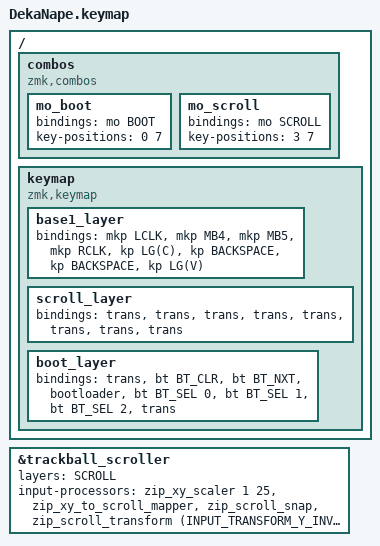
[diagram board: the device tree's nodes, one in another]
/*
 * Copyright (c) 2020 The ZMK Contributors
 *
 * SPDX-License-Identifier: MIT
 */

#include <input/processors.dtsi>
#include <dt-bindings/zmk/mouse.h>
#include <scroll-snap.dtsi>
#include <behaviors.dtsi>
#include <dt-bindings/zmk/bt.h>
#include <dt-bindings/zmk/keys.h>
#include <dt-bindings/zmk/pointing.h>

#define BASE   0
#define SCROLL 1
#define BOOT   2

&trackball_scroller {
    layers = <SCROLL>;
    input-processors =
        <&zip_xy_scaler 1 25 &zip_xy_to_scroll_mapper &zip_scroll_snap>,
        <&zip_scroll_transform (INPUT_TRANSFORM_Y_INVERT)>;
};

/ {
    combos {
        compatible = "zmk,combos";

        mo_boot {
            bindings = <&mo BOOT>;
            key-positions = <0 7>;
        };

        mo_scroll {
            bindings = <&mo SCROLL>;
            key-positions = <3 7>;
        };
    };

    keymap {
        compatible = "zmk,keymap";

        base1_layer {
            bindings = <
&mkp LCLK  &mkp MB4  &mkp MB5  &mkp RCLK  &kp LG(C)  &kp BACKSPACE  &kp BACKSPACE  &kp LG(V)
            >;
        };

        scroll_layer {
            bindings = <
&trans  &trans  &trans  &trans  &trans  &trans  &trans  &trans
            >;
        };

        boot_layer {
            bindings = <
&trans  &bt BT_CLR  &bt BT_NXT  &bootloader  &bt BT_SEL 0  &bt BT_SEL 1  &bt BT_SEL 2  &trans
            >;
        };
    };
};
